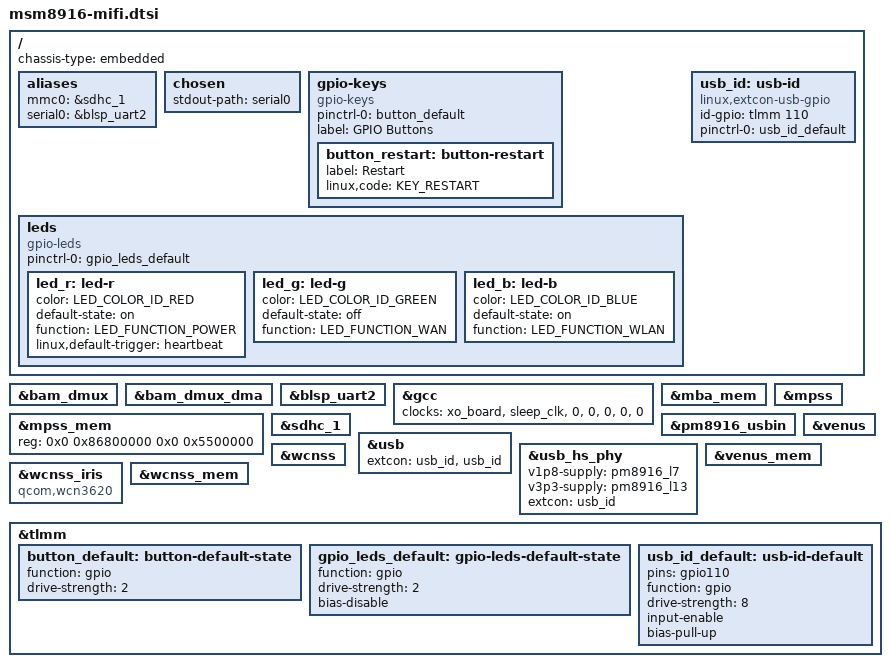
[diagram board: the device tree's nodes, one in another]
// SPDX-License-Identifier: GPL-2.0-only

#include "msm8916-pm8916.dtsi"

#include <dt-bindings/gpio/gpio.h>
#include <dt-bindings/leds/common.h>

/ {
	chassis-type = "embedded";

	aliases {
	        mmc0 = &sdhc_1; /* eMMC */
		serial0 = &blsp_uart2;
	};

	chosen {
		stdout-path = "serial0";
	};

	gpio-keys {
		compatible = "gpio-keys";

		pinctrl-0 = <&button_default>;
		pinctrl-names = "default";

		label = "GPIO Buttons";

		/* GPIO is board-specific */
		button_restart: button-restart {
			label = "Restart";
			linux,code = <KEY_RESTART>;
		};
	};

	leds: leds {
		compatible = "gpio-leds";

		pinctrl-0 = <&gpio_leds_default>;
		pinctrl-names = "default";

		/*
		 * GPIOs are board-specific.
		 * Functions and default-states defined here are fallbacks.
		 * Feel free to override them if your board is different.
		 */
		led_r: led-r {
			color = <LED_COLOR_ID_RED>;
			default-state = "on";
			function = LED_FUNCTION_POWER;
			linux,default-trigger = "heartbeat";
		};

		led_g: led-g {
			color = <LED_COLOR_ID_GREEN>;
			default-state = "off";
			function = LED_FUNCTION_WAN;
		};

		led_b: led-b {
			color = <LED_COLOR_ID_BLUE>;
			default-state = "on";
			function = LED_FUNCTION_WLAN;
		};
	};
	usb_id: usb-id {
		compatible = "linux,extcon-usb-gpio";
		id-gpio = <&tlmm 110 GPIO_ACTIVE_HIGH>;
		pinctrl-names = "default";
		pinctrl-0 = <&usb_id_default>;
	};
};

&bam_dmux {
	status = "okay";
};

&bam_dmux_dma {
	status = "okay";
};

&blsp_uart2 {
	status = "okay";
};

/* Remove &dsi_phy0 from clocks to make sure that gcc probes with display disabled */
&gcc {
	clocks = <&xo_board>, <&sleep_clk>, <0>, <0>, <0>, <0>, <0>;
};

&mba_mem {
	status = "okay";
};

&mpss {
	status = "okay";
};

&mpss_mem {
	reg = <0x0 0x86800000 0x0 0x5500000>;
	status = "okay";
};

&pm8916_usbin {
	status = "okay";
};

&sdhc_1 {
	status = "okay";
};

&usb {
	status = "okay";
	extcon = <&usb_id>, <&usb_id>;
};

&usb_hs_phy {
	v1p8-supply = <&pm8916_l7>;
	v3p3-supply = <&pm8916_l13>;
	extcon = <&usb_id>;
};

&venus {
	status = "okay";
};

&venus_mem {
	status = "okay";
};

&wcnss {
	status = "okay";
};

&wcnss_iris {
	compatible = "qcom,wcn3620";
};

&wcnss_mem {
	status = "okay";
};

&tlmm {
	/* pins are board-specific */
	button_default: button-default-state {
		function = "gpio";
		drive-strength = <2>;
	};

	gpio_leds_default: gpio-leds-default-state {
		function = "gpio";
		drive-strength = <2>;
		bias-disable;
	};
	
	usb_id_default: usb-id-default {
		pins = "gpio110";
		function = "gpio";

		drive-strength = <8>;
		input-enable;
		bias-pull-up;
	};
};
